AUTOSAR XML (schema 4.0)
package /Battery_EV_Components
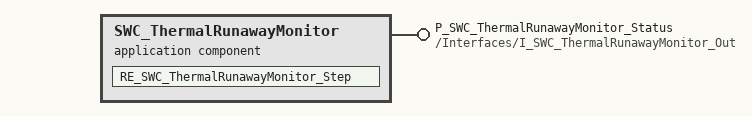
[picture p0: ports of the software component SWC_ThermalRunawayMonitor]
  application sw component type SWC_ThermalRunawayMonitor  # AUTOSAR Application SWC SWC_ThermalRunawayMonitor for Battery EV Safety
    provide port P_SWC_ThermalRunawayMonitor_Status: provided-interface=/Interfaces/I_SWC_ThermalRunawayMonitor_Out
    behavior SWC_ThermalRunawayMonitor_Behavior
      runnable RE_SWC_ThermalRunawayMonitor_Step: symbol=SWC_ThermalRunawayMonitor_Step
  sender receiver interface I_SWC_ThermalRunawayMonitor_Out
    data DE_SWC_ThermalRunawayMonitor_Health: type=/AUTOSAR/Platform/uint32
